# M3351 register map
File version: 1.0
Registers are 32-bit, read-write, reset 0x0 unless marked. A register's access mark holds for its fields unless they carry their own. Offsets are from the block's base; [hi:lo] are bit positions; 'fields as' and 'values as' point back to an identical list.

## UI2C0 — USCII2C Register Map
Base 0x400D0000; alternate view of UUART0
0x00 UI2C_CTL — USCI Control Register
  [2:0] FUNMODE — Function Mode. This bit field selects the protocol for this USCI controller. Selecting a protocol that is not available or a reserved combination disables the USCI. When switching between two protocols, the USCI has to be disabled before selecting a new protocol. Simultaneously, the USCI will be reset when user write 000 to FUNMODE. Note: Other bit combinations are reserved.
    0=The USCI is disabled. All protocol related state machines are set to idle state; 1=The SPI protocol is selected; 2=The UART protocol is selected; 4=The I2C protocol is selected
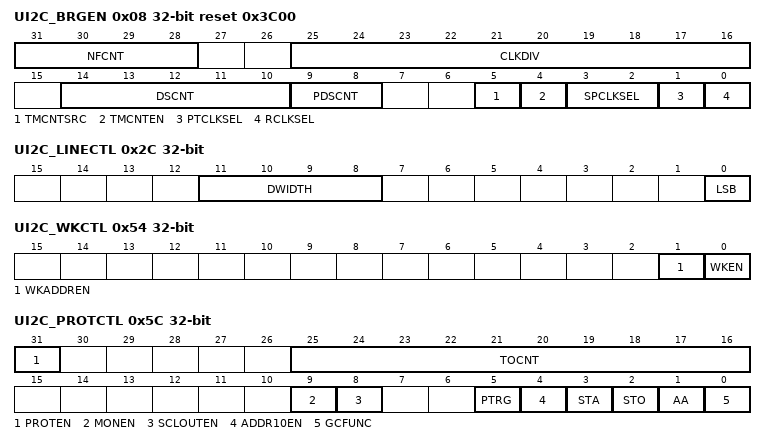
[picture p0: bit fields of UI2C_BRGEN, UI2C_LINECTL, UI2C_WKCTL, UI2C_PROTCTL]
0x08 UI2C_BRGEN reset 0x3C00 — USCI Baud Rate Generator Register
  [31:28] NFCNT — Noise Filter Count. The register bits control the input filter width. 0 : filter width 3*PCLK. 1 : filter width 4*PCLK. N : filter width (3+N)*PCKL. Note: Filter width Min :3*PCLK, Max : 18*PCLK
  [25:16] CLKDIV — Clock Divider. Note: The minimum value of DIVIDER is 9 for USCI_I2C.
  [14:10] DSCNT — Denominator for Sample Counter. This bit field defines the divide ratio of the sample clock fSAMP_CLK. Note: The maximum value of DSCNT is 0xF on UART mode and suggest to set over 4 to confirm the receiver data is sampled in right value.
  [9:8] PDSCNT — Pre-divider for Sample Counter
  [5] TMCNTSRC — Time Measurement Counter Clock Source Selection
    0=Time measurement counter with fPROT_CLK; 1=Time measurement counter with fDIV_CLK
  [4] TMCNTEN — Time Measurement Counter Enable Bit. This bit enables the 10-bit timing measurement counter.
    0=Time measurement counter is Disabled; 1=Time measurement counter is Enabled
  [3:2] SPCLKSEL — Sample Clock Source Selection. This bit field used for the clock source selection of a sample clock (fSAMP_CLK) for the protocol processor.
    0=fSAMP_CLK = fDIV_CLK; 1=fSAMP_CLK = fPROT_CLK; 2=fSAMP_CLK = fSCLK; 3=fSAMP_CLK = fREF_CLK
  [1] PTCLKSEL — Protocol Clock Source Selection. This bit selects the source signal of protocol clock (fPROT_CLK).
    0=Reference clock fREF_CLK; 1=fREF_CLK2 (its frequency is half of fREF_CLK)
  [0] RCLKSEL — Reference Clock Source Selection. This bit selects the source signal of reference clock (fREF_CLK).
    0=Peripheral device clock fPCLK
0x2C UI2C_LINECTL — USCI Line Control Register
  [11:8] DWIDTH — Word Length of Transmission. This bit field defines the data word length (amount of bits) for reception and transmission. The data word is always right-aligned in the data buffer. USCI support word length from 4 to 16 bits. 0x0: The data word contains 16 bits located at bit positions [15:0]. 0x1: Reserved. 0x2: Reserved. 0x3: Reserved. 0x4: The data word contains 4 bits located at bit positions [3:0]. 0x5: The data word contains 5 bits located at bit positions [4:0]. ... 0xF: The data word contains 15 bits located at bit positions [14:0].
  [0] LSB — LSB First Transmission Selection
    0=The MSB, which bit of transmit/receive data buffer depends on the setting of DWIDTH, is transmitted/received first; 1=The LSB, the bit 0 of data buffer, will be transmitted/received first
0x30 UI2C_TXDAT wo — USCI Transmit Data Register
  [15:0] TXDAT — Transmit Data. Software can use this bit field to write 16-bit transmit data for transmission.
0x34 UI2C_RXDAT ro — USCI Receive Data Register
  [15:0] RXDAT — Received Data. This bit field monitors the received data which stored in receive data buffer. Note: In I2C protocol, RXDAT[12:8] indicate the different transmission conditions which defined in I2C.
0x44 UI2C_DEVADDR0 — USCI Device Address Register 0
  [9:0] DEVADDR — Device Address. In I2C protocol, this bit field contains the programmed slave address. If the first received address byte are 1111 0AAXB, the AA bits are compared to the bits DEVADDR [9:8] to check for address match, where the X is R/W bit. Then the second address byte is also compared to DEVADDR [7:0]. Note 1: The DEVADDR [9:7] must be set 3'b000 when I2C operating in 7-bit address mode. Note 2: When software set 10'h000, the address cannot be used.
0x48 UI2C_DEVADDR1 — USCI Device Address Register 1
  fields as UI2C_DEVADDR0
0x4C UI2C_ADDRMSK0 — USCI Device Address Mask Register 0
  [9:0] ADDRMSK — USCI Device Address Mask. USCI support multiple address recognition with two address mask register. When the bit in the address mask register is set to one, it means the received corresponding address bit is don't-care. If the bit is set to zero, that means the received corresponding register bit should be exact the same as address register. Note: The wake-up function cannot use address mask in 10-bit mode
    0=Mask Disabled (the received corresponding register bit should be exact the same as address register.); 1=Mask Enabled (the received corresponding address bit is don't care.)
0x50 UI2C_ADDRMSK1 — USCI Device Address Mask Register 1
  fields as UI2C_ADDRMSK0
0x54 UI2C_WKCTL — USCI Wake-up Control Register
  [1] WKADDREN — Wake-up Address Match Enable Bit
    0=The chip is woken up according to START signal; 1=The chip is woken up according to address match
  [0] WKEN — Wake-up Enable Bit
    0=Wake-up function Disabled; 1=Wake-up function Enabled
0x58 UI2C_WKSTS — USCI Wake-up Status Register
  [0] WKF — Wake-up Flag. When chip is woken up from Power-down mode, this bit is set to 1. Software can write 1 to clear this bit.
0x5C UI2C_PROTCTL — USCI Protocol Control Register
  [31] PROTEN — I2C Protocol Enable Bit
    0=I2C Protocol Disabled; 1=I2C Protocol Enabled
  [25:16] TOCNT — Time-out Clock Cycle. This bit field indicates how many clock cycle selected by TMCNTSRC (UI2C_BRGEN [5]) when each interrupt flags are clear. The time-out is enable when TOCNT bigger than 0. Note: The TMCNTSRC (UI2C_BRGEN [5]) must be set zero on I2C mode.
  [9] MONEN — Monitor Mode Enable Bit. This bit enables monitor mode. In monitor mode the SDA output will be put in high impedance mode. This prevents the I2C module from outputting data of any kind (including ACK) onto the I2C data bus. Note: Depending on the state of the SCLOUTEN bit, the SCL output may be also forced high, preventing the module from having control over the I2C clock line.
    0=The monitor mode Disabled; 1=The monitor mode Enabled
  [8] SCLOUTEN — SCL Output Enable Bit. This bit enables monitor pulling SCL to low. This monitor will pull SCL to low until it has had time to respond to an I2C interrupt.
    0=SCL output will be forced high due to open drain mechanism; 1=I2C module may act as a slave peripheral just like in normal operation, the I2C holds the clock line low until it has had time to clear I2C interrupt
  [5] PTRG — I2C Protocol Trigger (Write Only). When a new state is present in the UI2C_PROTSTS register, if the related interrupt enable bits are set, the I2C interrupt is requested. It must write one by software to this bit after the related interrupt flags are set to 1 and the I2C protocol function will go ahead until the STOP is active or the PROTEN is disabled.
    0=I2C's stretch disabled and the I2C protocol function will go ahead; 1=I2C's stretch is active
  [4] ADDR10EN — Address 10-bit Function Enable Bit
    0=Address match 10 bit function Disabled; 1=Address match 10 bit function Enabled
  [3] STA — I2C START Control. Setting STA to logic 1 to enter Master mode, the I2C hardware sends a START or repeat START condition to bus when the bus is free.
  [2] STO — I2C STOP Control
  [1] AA — Assert Acknowledge Control
  [0] GCFUNC — General Call Function. Note: When ADDR10EN (UI2C_PROTCTL [4]) is set, don't set this bit.
    0=General Call Function Disabled; 1=General Call Function Enabled
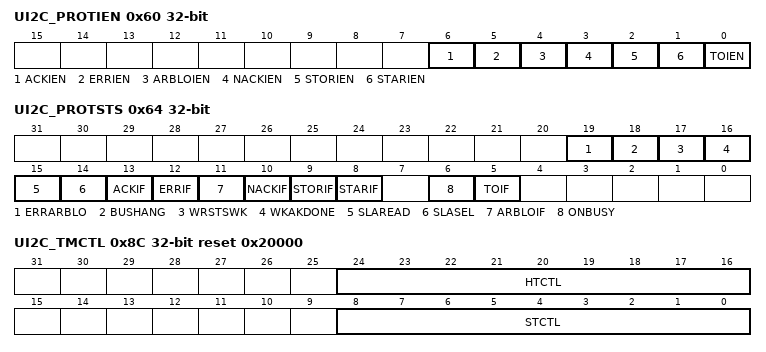
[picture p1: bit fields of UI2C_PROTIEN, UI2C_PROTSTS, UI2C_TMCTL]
0x60 UI2C_PROTIEN — USCI Protocol Interrupt Enable Register
  [6] ACKIEN — Acknowledge Interrupt Enable Bit. This bit enables the generation of a protocol interrupt if an acknowledge is detected by a master.
    0=The acknowledge interrupt Disabled; 1=The acknowledge interrupt Enabled
  [5] ERRIEN — Error Interrupt Enable Bit. This bit enables the generation of a protocol interrupt if an I2C error condition is detected (indicated by ERRIF (UI2C_PROTSTS [12])).
    0=The error interrupt Disabled; 1=The error interrupt Enabled
  [4] ARBLOIEN — Arbitration Lost Interrupt Enable Bit. This bit enables the generation of a protocol interrupt if an arbitration lost event is detected.
    0=The arbitration lost interrupt Disabled; 1=The arbitration lost interrupt Enabled
  [3] NACKIEN — Non - Acknowledge Interrupt Enable Bit. This bit enables the generation of a protocol interrupt if a Non - acknowledge is detected by a master.
    0=The non - acknowledge interrupt Disabled; 1=The non - acknowledge interrupt Enabled
  [2] STORIEN — STOP Condition Received Interrupt Enable Bit. This bit enables the generation of a protocol interrupt if a STOP condition is detected.
    0=The stop condition interrupt Disabled; 1=The stop condition interrupt Enabled
  [1] STARIEN — START Condition Received Interrupt Enable Bit. This bit enables the generation of a protocol interrupt if a START condition is detected.
    0=The start condition interrupt Disabled; 1=The start condition interrupt Enabled
  [0] TOIEN — Time-out Interrupt Enable Bit. In I2C protocol, this bit enables the interrupt generation in case of a time-out event.
    0=The time-out interrupt Disabled; 1=The time-out interrupt Enabled
0x64 UI2C_PROTSTS — USCI Protocol Status Register
  [19] ERRARBLO — Error Arbitration Lost. This bit indicates bus arbitration lost due to bigger noise which is can't be filtered by input processor. The I2C can send start condition when ERRARBLO is set. Thus this bit doesn't be cared on slave mode. Note 1: This bit has no interrupt signal, and it will be cleared automatically by hardware when a START condition is present. Note 2: This bit is read only.
    0=The bus is normal status for transmission; 1=The bus is error arbitration lost status for transmission
  [18] BUSHANG — Bus Hang-up. This bit indicates bus hang-up status. There is 4-bit counter count when SCL hold high and refer fSAMP_CLK. The hang-up counter will count to overflow and set this bit when SDA is low. The counter will be reset by falling edge of SCL signal. Note 1: This bit has no interrupt signal, and it will be cleared automatically by hardware when a START condition is present. Note 2: This bit is read only.
    0=The bus is normal status for transmission; 1=The bus is hang-up status for transmission
  [17] WRSTSWK — Read/Write Status Bit in Address Wake-up Frame. Note: This bit is read only.
    0=Write command be record on the address match wake-up frame; 1=Read command be record on the address match wake-up frame
  [16] WKAKDONE — Wake-up Address Frame Acknowledge Bit Done. Note 1: This bit can't release when WKF is set. Note 2: This bit is read only.
    0=The ACK bit cycle of address match frame isn't done; 1=The ACK bit cycle of address match frame is done in power-down
  [15] SLAREAD — Slave Read Request Status. This bit indicates that a slave read request has been detected. Note 1: This bit has no interrupt signal, and it will be cleared automatically by hardware. Note 2: This bit is read only.
    0=A slave R/W bit is 1 has not been detected; 1=A slave R/W bit is 1 has been detected
  [14] SLASEL — Slave Select Status. This bit indicates that this device has been selected as slave. Note 1: This bit has no interrupt signal, and it will be cleared automatically by hardware. Note 2: This bit is read only.
    0=The device is not selected as slave; 1=The device is selected as slave
  [13] ACKIF — Acknowledge Received Interrupt Flag. Note: This bit is cleared by software writing 1 into this bit
    0=An acknowledge has not been received; 1=An acknowledge has been received
  [12] ERRIF — Error Interrupt Flag. Note 1: This bit is cleared by software writing 1 into this bit. Note 2: This bit is set for slave mode, and user must write 1 into STO register to the defined 'not addressed' slave mode.
    0=An I2C error has not been detected; 1=An I2C error has been detected
  [11] ARBLOIF — Arbitration Lost Interrupt Flag. Note: This bit is cleared by software writing 1 into this bit.
    0=An arbitration has not been lost; 1=An arbitration has been lost
  [10] NACKIF — Non - Acknowledge Received Interrupt Flag. Note: This bit is cleared by software writing 1 into this bit.
    0=A non - acknowledge has not been received; 1=A non - acknowledge has been received
  [9] STORIF — Stop Condition Received Interrupt Flag. Note: This bit is cleared by software writing 1 into this bit.
    0=A stop condition has not yet been detected; 1=A stop condition has been detected
  [8] STARIF — Start Condition Received Interrupt Flag. This bit indicates that a start condition or repeated start condition has been detected on master mode. However, this bit also indicates that a repeated start condition has been detected on slave mode. Note: This bit is cleared by software writing 1 into this bit.
    0=A start condition has not yet been detected; 1=A start condition has been detected
  [6] ONBUSY — On Bus Busy. Indicates that a communication is in progress on the bus. It is set by hardware when a START condition is detected. It is cleared by hardware when a STOP condition is detected. Note: This bit is read only.
    0=The bus is IDLE (both SCLK and SDA High); 1=The bus is busy
  [5] TOIF — Time-out Interrupt Flag. Note: This bit is cleared by software writing 1 into this bit.
    0=A time-out interrupt status has not occurred; 1=A time-out interrupt status has occurred
0x8C UI2C_TMCTL reset 0x20000 — I2C Timing Configure Control Register
  [24:16] HTCTL — Hold Time Configure Control. This field is used to generate the delay timing between SCL falling edge SDA edge in transmission mode.
  [8:0] STCTL — Setup Time Configure Control. This field is used to generate a delay timing between SDA edge and SCL rising edge in transmission mode..

## UI2C1 — USCII2C Register Map
Base 0x400D1000; alternate view of UUART1
Registers as UI2C0.

## UI2C0_NS — USCII2CNS Register Map
Base 0x500D0000; alternate view of UUART0_NS
Registers as UI2C0.

## UI2C1_NS — USCII2CNS Register Map
Base 0x500D1000; alternate view of UUART1_NS
Registers as UI2C0.
